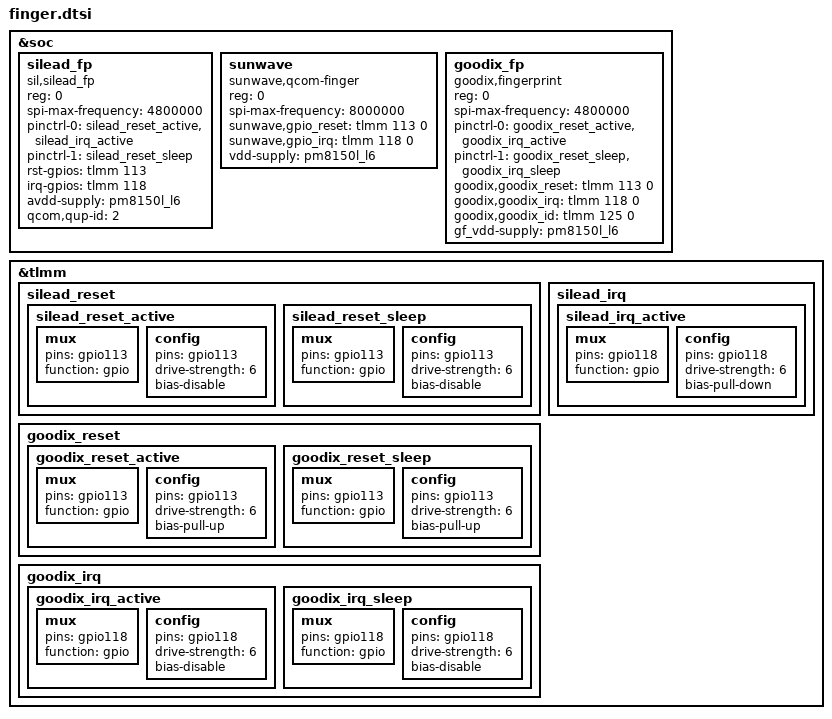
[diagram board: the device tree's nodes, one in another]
/*
 * nubia NX629J finger dts
 */
&soc {
        /* used for fingerprint device as platform device added by nubia start*/
	silead_fp{
		status = "ok";
		reg = <0>;
		compatible = "sil,silead_fp";
		spi-max-frequency = <4800000>;
		pinctrl-names = "spi_default", "spi_sleep";
		pinctrl-0 = <&silead_reset_active &silead_irq_active>;
		pinctrl-1 = <&silead_reset_sleep>;
		rst-gpios = <&tlmm 113 0>;
		irq-gpios = <&tlmm 118 0>;
		avdd-supply = <&pm8150l_l6>;
		/*vddio-supply = <&pm8998_l15>;*/
		qcom,qup-id = <2>;
	};
	/* used for fingerprint device as platform device added by nubia end*/
};

/*****finger pinctrl start *****/
&tlmm {
		silead_reset {
			silead_reset_active: silead_reset_active {
				mux {
					pins = "gpio113";
					function = "gpio";
				};

				config {
					pins = "gpio113";
					drive-strength = <6>;
					bias-disable;
				};
			};

			silead_reset_sleep: silead_reset_sleep {
				mux {
					pins = "gpio113";
					function = "gpio";
				};

				config {
					pins = "gpio113";
					drive-strength = <6>;
					bias-disable;
				};
			};
		};

		silead_irq {
			silead_irq_active: silead_irq_active {
				mux {
					pins = "gpio118";
					function = "gpio";
				};

				config {
					pins = "gpio118";
					drive-strength = <6>;
					bias-pull-down;
				};
			};

		};
};


&soc {
        /* used for fingerprint device as platform device added by nubia start*/
	sunwave{
	        status = "ok";
	        reg = <0>;
	        compatible = "sunwave,qcom-finger";
	        spi-max-frequency = <8000000>;
	        sunwave,gpio_reset = <&tlmm 113 0>;
	        sunwave,gpio_irq = <&tlmm 118 0>;
			vdd-supply = <&pm8150l_l6>;
	};
	/* used for fingerprint device as platform device added by nubia end*/
};
&soc {
        /* used for fingerprint device as platform device added by nubia start*/
	goodix_fp{
	        status = "ok";
	        reg = <0>;
	        compatible = "goodix,fingerprint";
	        spi-max-frequency = <4800000>;
	        pinctrl-names = "gf_fp_active", "gf_fp_suspend";
	        pinctrl-0 = <&goodix_reset_active &goodix_irq_active>;
	        pinctrl-1 = <&goodix_reset_sleep &goodix_irq_sleep>;
	        goodix,goodix_reset = <&tlmm 113 0>;
	        goodix,goodix_irq = <&tlmm 118 0>;
			goodix,goodix_id = <&tlmm 125 0>;
			gf_vdd-supply = <&pm8150l_l6>;
	};
	/* used for fingerprint device as platform device added by nubia end*/
};

/*****finger pinctrl start *****/
&tlmm {
		goodix_reset {
			goodix_reset_active: goodix_reset_active {
				mux {
					pins = "gpio113";
					function = "gpio";
				};

				config {
					pins = "gpio113";
					drive-strength = <6>;
					bias-pull-up;
				};
			};

			goodix_reset_sleep: goodix_reset_sleep {
				mux {
					pins = "gpio113";
					function = "gpio";
				};

				config {
					pins = "gpio113";
					drive-strength = <6>;
					bias-pull-up;
				};
			};
		};

		goodix_irq {
			goodix_irq_active: goodix_irq_active {
				mux {
					pins = "gpio118";
					function = "gpio";
				};

				config {
					pins = "gpio118";
					drive-strength = <6>;
					bias-disable;
				};
			};

			goodix_irq_sleep: goodix_irq_sleep {
				mux {
					pins = "gpio118";
					function = "gpio";
				};

				config {
					pins = "gpio118";
					drive-strength = <6>;
					bias-disable;
				};
			};
		};
};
